# FSS0_FSS0_FOTA_GENREGS_0FC60000h register map
Vendor: Texas Instruments
Peripheral module from a debugger description file (folder AM275x).
Registers are 32-bit, access not given, reset 0x0 unless marked. A register's access mark holds for its fields unless they carry their own. Offsets are as the file gives them; lines under a group give offsets from that group; [hi:lo] are bit positions; {n}, {i} and the like mark numbered series; 'fields as' and 'values as' point back to an identical list; <NAME> marks a mode.

## FSS0_fota_genregs
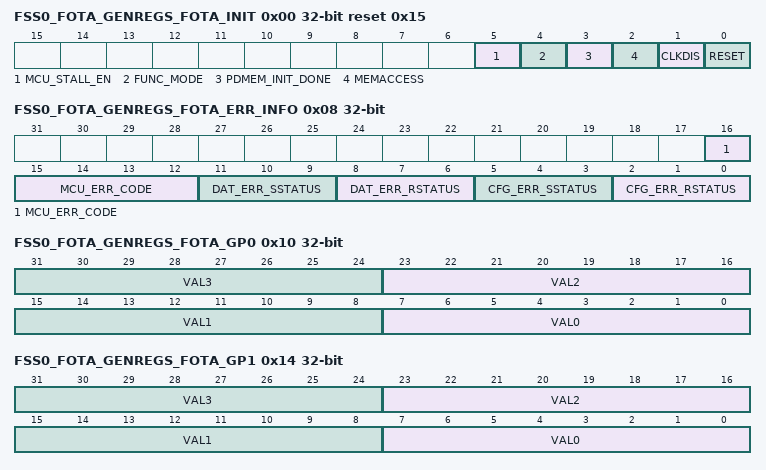
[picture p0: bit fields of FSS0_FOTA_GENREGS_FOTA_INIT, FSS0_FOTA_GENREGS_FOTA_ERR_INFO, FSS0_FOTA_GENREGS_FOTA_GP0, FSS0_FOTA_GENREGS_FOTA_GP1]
0x00 FSS0_FOTA_GENREGS_FOTA_INIT access per field reset 0x15 — This register is used to initialize FOTA logic including M8051EW MCU
  [5] MCU_STALL_EN rw — Reserved field. This field SHALL be retained at 0, which is the default value. Reset Source: vbus_mod_g_rst_n
  [4] FUNC_MODE rw — This bit is used for selection functional or debug mode. 1'b1 - M8051EW uses functional mode for regular operation. 1'b0 - M8051EW uses debug mode for debug using JTAG. Reset Source: vbus_mod_g_rst_n
  [3] PDMEM_INIT_DONE ro — This bit indicates that FOTA program/data memory RAM initialization is done. Until this bit is set, access to program/data memory should not be performed by software. Reset Source: vbus_mod_g_rst_n
  [2] MEMACCESS rw — This bit provides SOC CPU access to program/data memory and internal memory through FSS config interface when set. If clear, these M8051EW memories are not accessible through config interface and is fully under the control of M8051EW. Software has to ensure that M8051EW is in reset by setting bit 0 of this register when memaccess is set. Reset Source: vbus_mod_g_rst_n
  [1] CLKDIS rw — This bit holds M8051EW core clock gated when set to 1'b1. Clock to M8051EW is enabled at reset. SOC software sets this bit to put M8051EW and other FOTA logic in low power state when not used by enabling clock gating. Reset Source: vbus_mod_g_rst_n
  [0] RESET rw — This bit holds M8051EW core in reset when set to 1'b1. System firmware clears this bit after setting up program and data memories. Reset Source: vbus_mod_g_rst_n
0x04 FSS0_FOTA_GENREGS_FOTA_CTRL — This register is used to start M8051EW firmware.
  [0] GO — SOC CPU sets this bit to indicate to M8051EW firmware that it can start the next FOTA page write. Once go is set, SOC software has to ensure that it is set again only after receiving an interrupt (completion or error) from M8051EW. If this requirement is not followed, it could result in M8051EW firmware repeating the FOTA write erroneously.A write to this register causes an indirect write to ESFR space for M8051EW. Firmware polls until ESFR GO bit is set and then starts the FOTA write sequence. This bit is cleared by hardware when the MCU has acknowledged GO through a write to the GO_ACK ESFR bit. Reset Source: vbus_mod_g_rst_n (access R/W1TS)
0x08 FSS0_FOTA_GENREGS_FOTA_ERR_INFO rw — This register contains information from FOTA logic used when servicing fsas_fota_stat_err_pend/fsas_fota_stat_err_req interrupt. This information is used in conjunction with FOTA interrupt status register ERR_STS_IRQ_STATUS_RAW. Software is expected to clear the fields in this register as it is not auto cleared by hardware.
  [16:12] MCU_ERR_CODE — This field contains error code reported by M8051EW firmware when ERR_STS_IRQ_STATUS_RAW.mcu_err is set. Error codes are software defined. Example encoding: 5'd0 - Flash error encountered during auto status polling, 5'd1 - Auto polling timeout error as status read from flash did not occur within expected time, 5'd2 - FOTA write timeout error where auto polling by M8051EW has indicated that flash write is still in progress after auto polling expiry time programmed in firmware, 5'd3 to 5'd31 - Reserved for future use. Reset Source: vbus_mod_g_rst_n
  [11:9] DAT_ERR_SSTATUS — This field contains read error status code when ERR_STS_IRQ_STATUS_RAW.dat_read_err interrupt flag is set Reset Source: vbus_mod_g_rst_n
  [8:6] DAT_ERR_RSTATUS — This field contains read error status code when ERR_STS_IRQ_STATUS_RAW.dat_read_err interrupt flag is set Reset Source: vbus_mod_g_rst_n
  [5:3] CFG_ERR_SSTATUS — This field contains read error status code when ERR_STS_IRQ_STATUS_RAW.cfg_read_err interrupt flag is set Reset Source: vbus_mod_g_rst_n
  [2:0] CFG_ERR_RSTATUS — This field contains read error status code when ERR_STS_IRQ_STATUS_RAW.cfg_read_err interrupt flag is set Reset Source: vbus_mod_g_rst_n
0x10 FSS0_FOTA_GENREGS_FOTA_GP0 rw — FOTA general purpose 0 register. SOC CPU can write to this register to pass information to M8051EW firmware through ESFR space.
  [8n+7:8n] VAL{n} (n=0..3) — General purpose 0 register val{n}. Reset Source: vbus_mod_g_rst_n
0x14 FSS0_FOTA_GENREGS_FOTA_GP1 ro — FOTA general purpose 1 register. M8051EW can write to this register to pass information to SOC CPU through ESFR space. Interpretation for this register is software defined and can be made context dependent if required.
  [8n+7:8n] VAL{n} (n=0..3) — General purpose 1 register val{n}. Reset Source: vbus_mod_g_rst_n
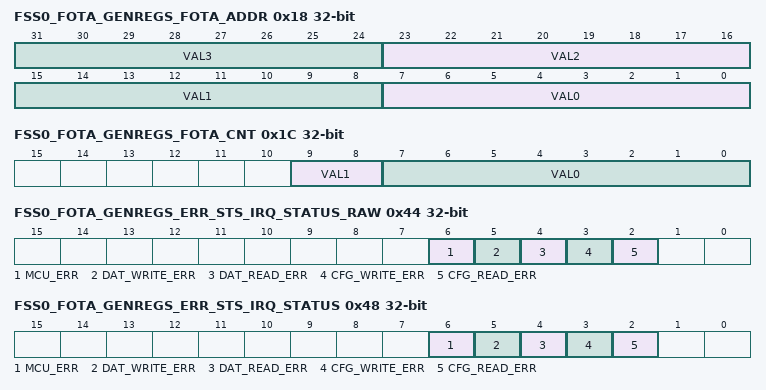
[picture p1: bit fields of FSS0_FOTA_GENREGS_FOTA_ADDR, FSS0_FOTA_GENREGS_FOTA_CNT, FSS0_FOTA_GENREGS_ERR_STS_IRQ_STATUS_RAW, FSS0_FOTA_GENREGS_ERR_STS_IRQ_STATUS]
0x18 FSS0_FOTA_GENREGS_FOTA_ADDR rw — FOTA operation write address register. SOC can write to this register to preload address for FOTA write instead of having 8051 firmware to setup address. Writing this register causes an indirect write to MCU_DAT_ADDR0-MCU_DAT_ADDR3 ESFR registers that are used by the VBUSM initiator as address for the FOTA write operation. Preloading these ESFR registers through this register removes the burden from 8051 firmware and reduces 8051 code size.
  [8n+7:8n] VAL{n} (n=0..3) — FOTA write address bits {8n+7}:{8n} Reset Source: vbus_mod_g_rst_n
0x1C FSS0_FOTA_GENREGS_FOTA_CNT rw — FOTA operation write byte count. SOC can write to this register to preload byte count based on the page size of the flash memory used. Writing this register causes an indirect write to MCU_DAT_CNT0-MCU_DAT_CNT1 ESFR registers that are used by the VBUSM initiator as the overall byte count for the FOTA write operation. VBUSM initiator performs the required number of 32-byte writes to match this overall byte count. Preloading these ESFR registers through this register removes the burden from 8051 firmware and reduces 8051 code size.
  [9:8] VAL1 — FOTA write byte count bits 9:8 Reset Source: vbus_mod_g_rst_n
  [7:0] VAL0 — FOTA write byte count bits 7:0 Reset Source: vbus_mod_g_rst_n
0x20 FSS0_FOTA_GENREGS_STS_IRQ_EOI wo — The End of Interrupt (EOI) Register allows the CPU to acknowledge completion of fsas_fota_stat_intr_req pulse interrupt. When this register is written to 1'b0, INTD logic used for converting fsas_ecc_intr_err_pend level interrupt to pulse will be re-armed. That is, if interrupt sources remain after writing this register to 1'b0, another pulse interrupt will be triggered by INTD. Conversely, if this register is not written to 1'b0 after fsas_fota_stat_intr_req pulse interrupt is received, then another pulse interrupt will not be received as INTD has not been re-armed. This register will be reset one cycle after it has been written to. Please note that the reason for writing 1'b0 is because there is only one interrupt (no interrupt aggregation) associated with this EOI and the INTD vector associated with this interrupt is 1'b0.
  [0] EOI_VECTOR — Write 1'b0 to acknowledge fsas_fota_stat_intr_req pulse interrupt. Reset Source: vbus_mod_g_rst_n
0x24 FSS0_FOTA_GENREGS_STS_IRQ_STATUS_RAW — The IRQ_STATUS_RAW register allows the interrupt sources to be manually set when writing a 1 to a specific bit. This register corresponds to fsas_fota_stat_intr_pend/fsas_fota_stat_intr_req interrupt output. Write 0: No action Write 1: Set event Read 0: No event pending Read 1: Event pending
  [0] FOTA_DONE — FOTA done raw status flag Reset Source: vbus_mod_g_rst_n (access R/W1TS)
0x28 FSS0_FOTA_GENREGS_STS_IRQ_STATUS — The IRQ_STATUS register allows the interrupt sources to be manually cleared when writing a 1 to a specific bit. This register corresponds to fsas_fota_stat_intr_pend/fsas_fota_stat_intr_req interrupt output. Write 0: No action Write 1: Clear event Read 0: No event pending Read 1: Event pending
  [0] FOTA_DONE — FOTA done status flag Reset Source: vbus_mod_g_rst_n (access R/W1TC)
0x2C FSS0_FOTA_GENREGS_STS_IRQ_ENABLE_SET — The IRQ_ENABLE_SET register allows the interrupt sources to be manually enabled when writing a 1 to a specific bit. This register corresponds to fsas_fota_stat_intr_pend/fsas_fota_stat_intr_req interrupt output. Write 0: No action Write 1: Enable event Read 0: Event is disabled Read 1: Event is enabled
  [0] FOTA_DONE — FOTA done enable set Reset Source: vbus_mod_g_rst_n (access R/W1TS)
0x30 FSS0_FOTA_GENREGS_STS_IRQ_ENABLE_CLR — The IRQ_ENABLE_CLR register allows the interrupt sources to be manually disabled when writing a 1 to a specific bit. This register corresponds to fsas_fota_stat_intr_pend/fsas_fota_stat_intr_req interrupt output. Write 0: No action Write 1: Disable event Read 0: Event is disabled Read 1: Event is enabled
  [0] FOTA_DONE — FOTA done enable clear Reset Source: vbus_mod_g_rst_n (access R/W1TC)
0x40 FSS0_FOTA_GENREGS_ERR_STS_IRQ_EOI wo — The End of Interrupt (EOI) Register allows the CPU to acknowledge completion of fsas_fota_stat_err_req pulse interrupt. When this register is written to 1'b0, INTD logic used for converting fsas_ecc_intr_err_pend level interrupt to pulse will be re-armed. That is, if interrupt sources remain after writing this register to 1'b0, another pulse interrupt will be triggered by INTD. Conversely, if this register is not written to 1'b0 after fsas_fota_stat_err_req pulse interrupt is received, then another pulse interrupt will not be received as INTD has not been re-armed. This register will be reset one cycle after it has been written to. Please note that the reason for writing 1'b0 is because there is only one interrupt (no interrupt aggregation) associated with this EOI and the INTD vector associated with this interrupt is 1'b0.
  [0] EOI_VECTOR — Write 1'b0 to acknowledge fsas_fota_stat_err_req pulse interrupt. Reset Source: vbus_mod_g_rst_n
0x44 FSS0_FOTA_GENREGS_ERR_STS_IRQ_STATUS_RAW — The IRQ_STATUS_RAW register allows the interrupt sources to be manually set when writing a 1 to a specific bit. This register corresponds to fsas_fota_stat_err_pend/fsas_fota_stat_err_req interrupt output. Write 0: No action Write 1: Set event Read 0: No event pending Read 1: Event pending
  [6] MCU_ERR — MCU error raw status flag. This is used to communicate error conditions encountered by 8051 firmware to SOC CPU. Error code is captured in FOTA_ERR_INFO.mcu_err_code field.If 8051 firmware runs into any error conditions, it sets the FOTA_ERR_STAT.mcu_err ESFR bit to 1'b1 and writes the corresponding error code into FOTA_ERR_STAT.mcu_err_code field. This causes an indirect writes to STATUS_RAW.mcu_err MMR and FOTA_ERR_INFO.mcu_err_code MMR. M8051EW firmware defines the error codes that result in this error. Please refer to FOTA_ERR_INFO.mcu_err_code MMR description for suggested encoding. Reset Source: vbus_mod_g_rst_n (access R/W1TS)
  [5] DAT_WRITE_ERR — Data interface write status error raw status flag. This error flag gets set when M8051EW performs a data write and error status is returned. The CBA error status code received is stored in FOTA_ERR_INFO.dat_err_sstatus register. Reset Source: vbus_mod_g_rst_n (access R/W1TS)
  [4] DAT_READ_ERR — Data interface read status error raw status flag. This error flag gets set when M8051EW performs a data read and error status is returned. The CBA error status code received is stored in FOTA_ERR_INFO.dat_err_rstatus register. Reset Source: vbus_mod_g_rst_n (access R/W1TS)
  [3] CFG_WRITE_ERR — Config interface write status error raw status flag. This error flag gets set when M8051EW performs a configuration write and error status is returned. The CBA error status code received is stored in FOTA_ERR_INFO.cfg_err_sstatus register. Reset Source: vbus_mod_g_rst_n (access R/W1TS)
  [2] CFG_READ_ERR — Config interface read status error raw status flag. This error flag gets set when M8051EW performs a configuration read and error status is returned. The CBA error status code received is stored in FOTA_ERR_INFO.cfg_err_rstatus register. Reset Source: vbus_mod_g_rst_n (access R/W1TS)
0x48 FSS0_FOTA_GENREGS_ERR_STS_IRQ_STATUS — The IRQ_STATUS register allows the interrupt sources to be manually cleared when writing a 1 to a specific bit. This register corresponds to fsas_fota_stat_err_pend/fsas_fota_stat_err_req interrupt output. Write 0: No action Write 1: Clear event Read 0: No event pending Read 1: Event pending
  [6] MCU_ERR — MCU error status flag Reset Source: vbus_mod_g_rst_n (access R/W1TC)
  [5] DAT_WRITE_ERR — Data interface write status error status flag Reset Source: vbus_mod_g_rst_n (access R/W1TC)
  [4] DAT_READ_ERR — Data interface read status error status flag Reset Source: vbus_mod_g_rst_n (access R/W1TC)
  [3] CFG_WRITE_ERR — Config interface write status error status flag Reset Source: vbus_mod_g_rst_n (access R/W1TC)
  [2] CFG_READ_ERR — Config interface read status error status flag Reset Source: vbus_mod_g_rst_n (access R/W1TC)
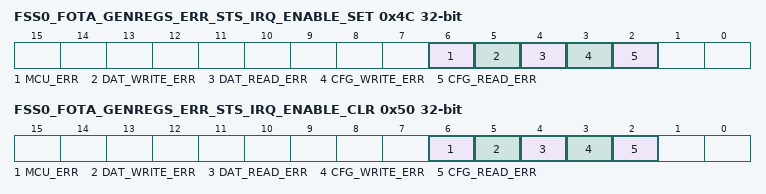
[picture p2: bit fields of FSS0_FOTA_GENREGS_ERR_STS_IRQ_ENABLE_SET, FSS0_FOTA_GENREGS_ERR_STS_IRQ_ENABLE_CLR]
0x4C FSS0_FOTA_GENREGS_ERR_STS_IRQ_ENABLE_SET — The IRQ_ENABLE_SET register allows the interrupt sources to be manually enabled when writing a 1 to a specific bit. This register corresponds to fsas_fota_stat_err_pend/fsas_fota_stat_err_req interrupt output. Write 0: No action Write 1: Enable event Read 0: Event is disabled Read 1: Event is enabled
  [6] MCU_ERR — MCU error enable set Reset Source: vbus_mod_g_rst_n (access R/W1TS)
  [5] DAT_WRITE_ERR — Data interface write status error enable set Reset Source: vbus_mod_g_rst_n (access R/W1TS)
  [4] DAT_READ_ERR — Data interface read status error enable set Reset Source: vbus_mod_g_rst_n (access R/W1TS)
  [3] CFG_WRITE_ERR — Config interface write status error enable set Reset Source: vbus_mod_g_rst_n (access R/W1TS)
  [2] CFG_READ_ERR — Config interface read status error enable set Reset Source: vbus_mod_g_rst_n (access R/W1TS)
0x50 FSS0_FOTA_GENREGS_ERR_STS_IRQ_ENABLE_CLR — The IRQ_ENABLE_CLR register allows the interrupt sources to be manually disabled when writing a 1 to a specific bit. This register corresponds to fsas_fota_stat_err_pend/fsas_fota_stat_err_req interrupt output. Write 0: No action Write 1: Disable event Read 0: Event is disabled Read 1: Event is enabled
  [6] MCU_ERR — MCU error enable clear Reset Source: vbus_mod_g_rst_n (access R/W1TC)
  [5] DAT_WRITE_ERR — Data interface write status error enable clear Reset Source: vbus_mod_g_rst_n (access R/W1TC)
  [4] DAT_READ_ERR — Data interface read status error enable clear Reset Source: vbus_mod_g_rst_n (access R/W1TC)
  [3] CFG_WRITE_ERR — Config interface write status error enable clear Reset Source: vbus_mod_g_rst_n (access R/W1TC)
  [2] CFG_READ_ERR — Config interface read status error enable clear Reset Source: vbus_mod_g_rst_n (access R/W1TC)
